# AVR16EA28 register map
Vendor: Atmel; File version: 1.0
CPU: other r0p0, little endian, no MPU, no FPU, 4 interrupt priority bits
Registers are 8-bit, read-write, reset 0x0 unless marked. A register's access mark holds for its fields unless they carry their own. Offsets are from the block's base; [hi:lo] are bit positions; {n}, {i} and the like mark numbered series; 'fields as' and 'values as' point back to an identical list.

## ADC0 — Analog to Digital Converter
Base 0x00800600
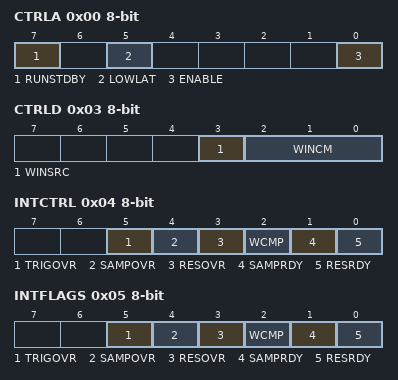
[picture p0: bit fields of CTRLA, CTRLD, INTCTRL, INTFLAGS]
0x00 CTRLA — Control A
  [7] RUNSTDBY — Run in Standby
  [5] LOWLAT — Low Latency
  [0] ENABLE — ADC Enable
0x01 CTRLB — Control B
  [3:0] PRESC — Prescaler Value
    0=DIV2 (System clock divided by 2); 1=DIV4 (System clock divided by 4); 2=DIV6 (System clock divided by 6); 3=DIV8 (System clock divided by 8); 4=DIV10 (System clock divided by 10); 5=DIV12 (System clock divided by 12); 6=DIV14 (System clock divided by 14); 7=DIV16 (System clock divided by 16); 8=DIV20 (System clock divided by 20); 9=DIV24 (System clock divided by 24); 10=DIV28 (System clock divided by 28); 11=DIV32 (System clock divided by 32); 12=DIV40 (System clock divided by 40); 13=DIV48 (System clock divided by 48); 14=DIV56 (System clock divided by 56); 15=DIV64 (System clock divided by 64)
0x02 CTRLC — Control C
  [2:0] REFSEL — Reference select
    0=VDD; 2=VREFA (External Reference); 4=1V024 (Internal 1.024V Reference); 5=2V048 (Internal 2.048V Reference); 6=4V096 (Internal 4.096V Reference); 7=2V500 (Internal 2.500V Reference)
0x03 CTRLD — Control D
  [3] WINSRC — Window Mode Source
    0=RESULT (Result register used as Window Comparator Source); 1=SAMPLE (Sample register used as Window Comparator Source)
  [2:0] WINCM — Window Comparator Mode
    0=NONE (No Window Comparison); 1=BELOW (Below Window); 2=ABOVE (Above Window); 3=INSIDE (Inside Window); 4=OUTSIDE (Outside Window)
0x04 INTCTRL — Interrupt Control
  [5] TRIGOVR — Trigger Overrun Interrupt Enable
  [4] SAMPOVR — Sample Overwrite Interrupt Enable
  [3] RESOVR — Result Overwrite Interrupt Enable
  [2] WCMP — Window Comparator Interrupt Enable
  [1] SAMPRDY — Sample Ready Interrupt Enable
  [0] RESRDY — Result Ready Interrupt Enable
0x05 INTFLAGS — Interrupt Flags
  [5] TRIGOVR — Trigger Overrun Interrupt Flag
  [4] SAMPOVR — Sample Overwrite Interrupt Flag
  [3] RESOVR — Result Overwrite Interrupt Flag
  [2] WCMP — Window Comparator Interrupt Flag
  [1] SAMPRDY — Sample Ready Interrupt Flag
  [0] RESRDY — Result Ready Interrupt Flag
0x06 STATUS ro
  [0] ADCBUSY
0x07 DBGCTRL — Debug Control
  [0] DBGRUN — Run in Debug Mode
0x08 CTRLE — Control E
  [7:0] SAMPDUR — Sample Duration
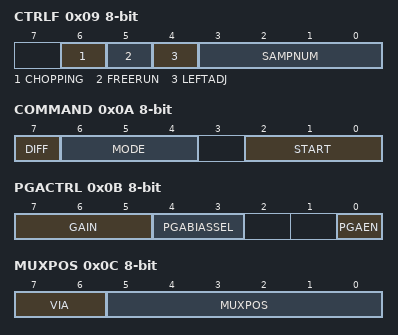
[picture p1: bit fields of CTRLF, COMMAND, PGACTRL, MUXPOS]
0x09 CTRLF — Control F
  [6] CHOPPING — Sign Chopping
    0=DISABLE (Sign Chopping Disabled); 1=ENABLE (Sign Chopping Enabled)
  [5] FREERUN — Free-Running mode
  [4] LEFTADJ — Left Adjust
  [3:0] SAMPNUM — Sample numbers
    0=NONE (No accumulation); 1=ACC2 (2 samples accumulated); 2=ACC4 (4 samples accumulated); 3=ACC8 (8 samples accumulated); 4=ACC16 (16 samples accumulated); 5=ACC32 (32 samples accumulated); 6=ACC64 (64 samples accumulated); 7=ACC128 (128 samples accumulated); 8=ACC256 (256 samples accumulated); 9=ACC512 (512 samples accumulated); 10=ACC1024 (1024 samples accumulated)
0x0A COMMAND
  [7] DIFF — Differential mode
  [6:4] MODE
    0=SINGLE_8BIT (Single Conversion with 8-bit resolution); 1=SINGLE_12BIT (Single Conversion with 12-bit resolution); 2=SERIES (Series with accumulation, separate trigger for every 12-bit conversion); 3=SERIES_SCALING (Series with accumulation and scaling, separate trigger for every 12-bit conversion); 4=BURST (Burst with accumulation, one trigger will run SAMPNUM 12-bit conversions); 5=BURST_SCALING (Burst with accumulation and scaling, one trigger will run SAMPNUM 12-bit conversions)
  [2:0] START — Start command
    0=STOP (Stop an ongoing conversion); 1=IMMEDIATE (Start a conversion immediately. This will be set back to STOP when the first conversion is done, unless Free-Running mode is enabled); 2=MUXPOS_WRITE (Start when MUXPOS register is written); 3=MUXNEG_WRITE (Start when MUXNEG register is written); 4=EVENT_TRIGGER (Start when an event is received)
0x0B PGACTRL — PGA Control
  [7:5] GAIN
    0=1x gain; 1=2X (2x gain); 2=4X (4x gain); 3=8X (8x gain); 4=16X (16x gain)
  [4:3] PGABIASSEL — PGA BIAS Select
    0=100PCT (100% BIAS current.); 1=75PCT (75% BIAS current. Usable for CLK_ADC<4.5MHz); 2=50PCT (50% BIAS current. Usable for CLK_ADC<3MHz); 3=25PCT (25% BIAS current. Usable for CLK_ADC<1.5MHz)
  [0] PGAEN — PGA Enable
0x0C MUXPOS — Positive Input Multiplexer
  [7:6] VIA
    0=DIRECT (Inputs connected directly to ADC); 1=PGA (Inputs connected via PGA)
  [5:0] MUXPOS — Analog Channel Selection Bits
    {v}=AIN{v} (ADC input pin {v}) (v=0..7); 16=AIN16 (ADC input pin 16); 17=AIN17 (ADC input pin 17); {v}=AIN{v} (ADC input pin {v}) (v=22..31); 48=GND (Ground); 49=VDD10 (VDD Divided by 10); 50=TEMPSENSE (Temperature Sensor); 56=DAC0 (Digital to Analog Converter 0)
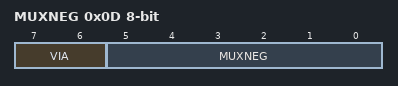
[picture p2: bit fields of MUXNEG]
0x0D MUXNEG — Negative Input Multiplexer
  [7:6] VIA
    values as MUXPOS.VIA
  [5:0] MUXNEG — Analog Channel Selection Bits
    {v}=AIN{v} (ADC input pin {v}) (v=0..7); 16=AIN16 (ADC input pin 16); 17=AIN17 (ADC input pin 17); {v}=AIN{v} (ADC input pin {v}) (v=22..31); 48=GND (Ground); 56=DAC0 (Digital to Analog Converter 0); 57=DACREF0 (AC0 DAC reference); 58=DACREF1 (AC1 DAC reference)
0x10 RESULT 32-bit ro (reset mask 0xFF)
0x14 SAMPLE 16-bit ro (reset mask 0xFF)
{0x18+i} TEMP{i} (i=0..2) — Temporary Data {i}
0x1C WINLT 16-bit (reset mask 0xFF) — Window Low Threshold
0x1E WINHT 16-bit (reset mask 0xFF) — Window High Threshold
